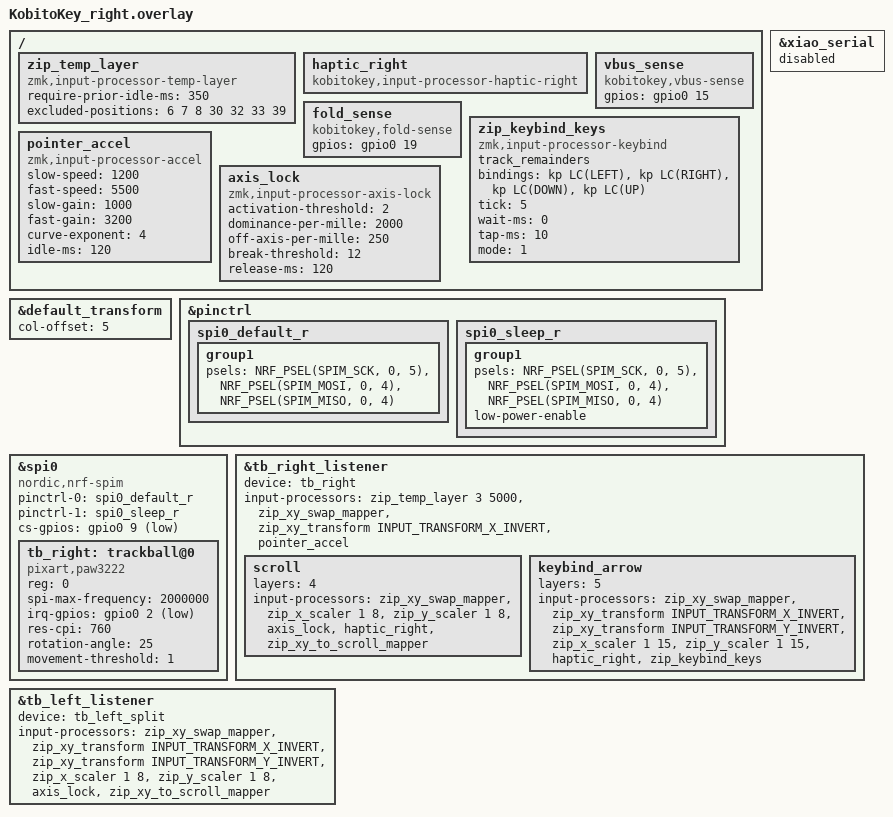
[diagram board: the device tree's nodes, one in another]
#include "kobitokey.dtsi"

#include <zephyr/dt-bindings/pinctrl/nrf-pinctrl.h>
#include <zephyr/dt-bindings/input/input-event-codes.h>
#include <dt-bindings/zmk/keys.h>
#include <input/processors.dtsi>

&xiao_serial { status = "disabled"; };

/* 列オフセット */
&default_transform { col-offset = <5>; };

&pinctrl {
    spi0_default_r: spi0_default_r { group1 {
        psels = <NRF_PSEL(SPIM_SCK,  0, 5)>,
                <NRF_PSEL(SPIM_MOSI, 0, 4)>,
                <NRF_PSEL(SPIM_MISO, 0, 4)>;
    }; };
    spi0_sleep_r: spi0_sleep_r { group1 {
        psels = <NRF_PSEL(SPIM_SCK,  0, 5)>,
                <NRF_PSEL(SPIM_MOSI, 0, 4)>,
                <NRF_PSEL(SPIM_MISO, 0, 4)>;
        low-power-enable;
    }; };
};

&spi0 {
    status = "okay";
    compatible = "nordic,nrf-spim";
    pinctrl-0 = <&spi0_default_r>;
    pinctrl-1 = <&spi0_sleep_r>;
    pinctrl-names = "default", "sleep";
    cs-gpios = <&gpio0 9 GPIO_ACTIVE_LOW>;

    tb_right: trackball@0 {
        status = "okay";
        compatible = "pixart,paw3222";
        reg = <0>;
        spi-max-frequency = <2000000>;
        irq-gpios = <&gpio0 2 (GPIO_ACTIVE_LOW | GPIO_PULL_UP)>;
        /* Closest valid PAW3222 setting to the PMW3610 build's 600 CPI. */
        /*
         * The PAW3222 cpi register steps in units of 38 (per datasheet),
         * so 760 = 20 * 38 is a real, exactly-representable value. This
         * previously read 600 only because the driver had been patched to
         * pretend the step was 30: 600/30 also wrote register value 20,
         * i.e. the sensor has actually been running at 760 cpi all along.
         * Keeping the effective cpi identical here means the 12-bit change
         * is the only variable in this build.
         */
        res-cpi = <760>;
        rotation-angle = <25>;
        movement-threshold = <1>;
        /* No force-awake: the PMW3610 build never forces its sensor awake
         * either, leaving rest-mode management entirely to the chip. */
    };
};

/ {
    /omit-if-no-ref/ zip_temp_layer: zip_temp_layer {
        compatible = "zmk,input-processor-temp-layer";
        #input-processor-cells = <2>;
        require-prior-idle-ms = <350>;
    };

    haptic_right: haptic_right {
        compatible = "kobitokey,input-processor-haptic-right";
        #input-processor-cells = <0>;
        status = "okay";
    };

    vbus_sense: vbus_sense {
        compatible = "kobitokey,vbus-sense";
        status = "okay";
        gpios = <&gpio0 15 GPIO_ACTIVE_HIGH>;
    };

    fold_sense: fold_sense {
        compatible = "kobitokey,fold-sense";
        status = "okay";
        /*
         * D12 / P0.19: Q2 makes HIGH=closed and LOW=open.
         *
         * No internal bias, deliberately. A pull-down was tried here on the
         * theory that the line floated, and the schematic says it does not:
         * Q2 pulls it down when the lid is open and R7 pulls it up when Q2
         * releases. R7 is 220k, though, and this part's internal pull-down
         * is around 13k, so enabling one does not bias a floating line, it
         * overrides R7 -- about 0.2V at the pin, read as open no matter
         * where the lid is. Leave the bias to the board.
         */
        gpios = <&gpio0 19 GPIO_ACTIVE_HIGH>;
    };

    zip_keybind_keys: zip_keybind_keys {
        compatible = "zmk,input-processor-keybind";
        #input-processor-cells = <0>;
        track_remainders;
        bindings = <&kp LC(LEFT)>,
                   <&kp LC(RIGHT)>,
                   <&kp LC(DOWN)>,
                   <&kp LC(UP)>;
        tick = <5>;
        wait-ms = <0>;
        tap-ms = <10>;
        /* Choose the dominant axis after a complete X/Y input frame. */
        mode = <1>;
        // threshold = <10>
        // max_threshold = <200>
        // max_pending_activations = <10>
    };

    /* Speed-dependent gain for the right ball's cursor. Slow movement
     * passes at 1.0 so aiming keeps the sensor's own precision; a hard
     * flick is stretched to 3.0x so the pointer can cross the screen
     * without turning the ball repeatedly. Thresholds are in input
     * counts per second at 760 cpi.
     *
     * The exponent is what stops it running away early: at 3, gain is
     * still only about 1.1x a third of the way up the range, so brisk
     * movement stays honest and the pull only arrives when the ball is
     * genuinely thrown. slow-speed sits at 900 for the same reason. */
    pointer_accel: pointer_accel {
        compatible = "zmk,input-processor-accel";
        #input-processor-cells = <0>;

        slow-speed = <1200>;
        fast-speed = <5500>;
        slow-gain = <1000>;
        fast-gain = <3200>;
        curve-exponent = <4>;
        idle-ms = <120>;
    };

    axis_lock: axis_lock {
        compatible = "zmk,input-processor-axis-lock";
        #input-processor-cells = <0>;

        /* Bias towards the direction of travel without ever taking the
         * other axis away, so a stroke runs straight but can still be
         * steered. dominance 2000 leaves genuinely diagonal movement
         * untouched; off-axis 250 damps wobble to a quarter rather than
         * removing it; break 12 gives the axis up as soon as a turn is
         * clearly deliberate. */
        activation-threshold = <2>;
        dominance-per-mille = <2000>;
        off-axis-per-mille = <250>;
        break-threshold = <12>;
        release-ms = <120>;
    };

};

&tb_right_listener {
    status = "okay";
    device = <&tb_right>;

    input-processors =
        <&zip_temp_layer 3 5000>,
        <&zip_xy_swap_mapper>,
        <&zip_xy_transform INPUT_TRANSFORM_X_INVERT>,
        <&pointer_accel>;


    scroll {
        layers = <4>;
        /* No inversions: macOS natural scrolling is off, so the
         * un-inverted direction is the one that matches. */
        input-processors =
            <&zip_xy_swap_mapper>,
            <&zip_x_scaler 1 8>,
            <&zip_y_scaler 1 8>,
            <&axis_lock>,
            <&haptic_right>,
            <&zip_xy_to_scroll_mapper>;
    };

    
    keybind_arrow { 
        layers = <5>;
        input-processors = 
            <&zip_xy_swap_mapper>,
            <&zip_xy_transform INPUT_TRANSFORM_X_INVERT>,
            <&zip_xy_transform INPUT_TRANSFORM_Y_INVERT>,
            <&zip_x_scaler 1 15>,
            <&zip_y_scaler 1 15>,
            <&haptic_right>,
            <&zip_keybind_keys>;
    };
};


/*
 * The left ball is scroll-only: it scrolls on every layer rather than
 * moving the cursor, so the two halves split the job between them --
 * right for pointing, left for scrolling. Because that is its permanent
 * role there is no layer-specific child node here; the chain below runs
 * unconditionally.
 *
 * Chain: the swap mapper to match the sensor's mounting orientation,
 * axis lock to keep a scroll from drifting sideways, and 1/8 scaling on
 * both axes before the mapper turns the movement into wheel events.
 * Both axes are inverted, to match macOS with natural scrolling off.
 *
 * Deliberately no haptic processor. That one runs on the central half and
 * would buzz the right-hand motor for movement of the left-hand ball,
 * which feels like the wrong half answering. The left half already gives
 * its own feedback locally, through the input callback in
 * kobitokey_haptic.c, on its own motor.
 */
&tb_left_listener {
    status = "okay";
    device = <&tb_left_split>;

    input-processors =
        <&zip_xy_swap_mapper>,
        <&zip_xy_transform INPUT_TRANSFORM_X_INVERT>,
        <&zip_xy_transform INPUT_TRANSFORM_Y_INVERT>,
        <&zip_x_scaler 1 8>,
        <&zip_y_scaler 1 8>,
        <&axis_lock>,
        <&zip_xy_to_scroll_mapper>;
};


&zip_temp_layer {
    excluded-positions = <
        6
        7
        8
        30
        32
        33
        39
    >;
};
